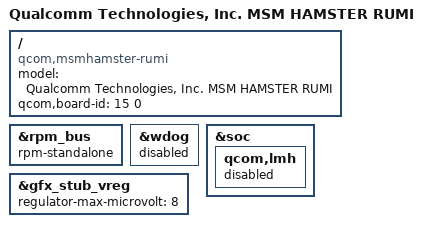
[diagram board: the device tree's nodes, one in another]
/* Copyright (c) 2016, The Linux Foundation. All rights reserved.
 *
 * This program is free software; you can redistribute it and/or modify
 * it under the terms of the GNU General Public License version 2 and
 * only version 2 as published by the Free Software Foundation.
 *
 * This program is distributed in the hope that it will be useful,
 * but WITHOUT ANY WARRANTY; without even the implied warranty of
 * MERCHANTABILITY or FITNESS FOR A PARTICULAR PURPOSE.  See the
 * GNU General Public License for more details.
 */


/dts-v1/;
/memreserve/ 0x90000000 0x00000100;

#include "msmhamster.dtsi"
#include "msm8998-rumi.dtsi"

/ {
	model = "Qualcomm Technologies, Inc. MSM HAMSTER RUMI";
	compatible = "qcom,msmhamster-rumi", "qcom,msmhamster", "qcom,rumi";
	qcom,board-id = <15 0>;
};

&rpm_bus {
	rpm-standalone;
};

&wdog {
	status = "disabled";
};

&soc {
	qcom,lmh {
		status = "disabled";
	};
};

&gfx_stub_vreg {
	regulator-max-microvolt = <8>;
	status = "okay";
};
